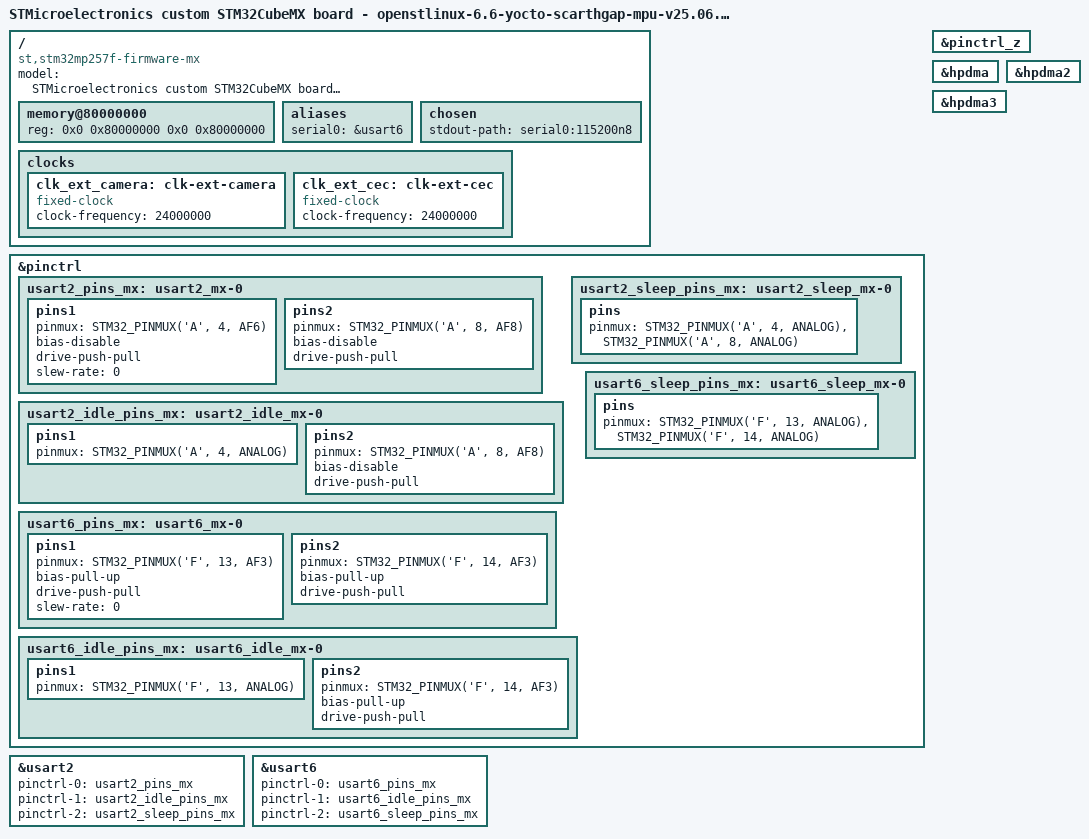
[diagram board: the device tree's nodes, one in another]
// SPDX-License-Identifier: (GPL-2.0-only OR BSD-3-Clause)
/*
 * Copyright (C) 2026, STMicroelectronics - All Rights Reserved
 * Author: STM32CubeMX code generation for STMicroelectronics.
 */

/* For more information on Device Tree configuration, please refer to
 * https://wiki.st.com/stm32mpu/wiki/Category:Device_tree_configuration
 */

/dts-v1/;

#include <dt-bindings/pinctrl/stm32-pinfunc.h>
#include "stm32mp257.dtsi"
#include "stm32mp25xf.dtsi"
#include "stm32mp257f-firmware-mx-resmem.dtsi"
#include "stm32mp25xxak-pinctrl.dtsi"

/* USER CODE BEGIN includes */
/* USER CODE END includes */

/ {
	model = "STMicroelectronics custom STM32CubeMX board - openstlinux-6.6-yocto-scarthgap-mpu-v25.06.11";
	compatible = "st,stm32mp257f-firmware-mx", "st,stm32mp257";

	memory@80000000 {
		device_type = "memory";
		reg = <0x0 0x80000000 0x0 0x80000000>;

		/* USER CODE BEGIN memory */
		/* USER CODE END memory */
	};

	/* USER CODE BEGIN root */
	aliases{
		serial0 = &usart6;
	};

	chosen{
		stdout-path = "serial0:115200n8";
	};
	/* USER CODE END root */

	clocks{

		/* USER CODE BEGIN clocks */
		clk_ext_camera:clk-ext-camera{
			#clock-cells = <0>;
			compatible = "fixed-clock";
			clock-frequency = <24000000>;
		};

		clk_ext_cec:clk-ext-cec{
			#clock-cells = <0>;
			compatible = "fixed-clock";
			clock-frequency = <24000000>;
		};
		/* USER CODE END clocks */
	};

}; /*root*/

&pinctrl {

	usart2_pins_mx: usart2_mx-0 {
		pins1 {
			pinmux = <STM32_PINMUX('A', 4, AF6)>; /* USART2_TX */
			bias-disable;
			drive-push-pull;
			slew-rate = <0>;
		};
		pins2 {
			pinmux = <STM32_PINMUX('A', 8, AF8)>; /* USART2_RX */
			bias-disable;
			drive-push-pull;
		};
	};

	usart2_idle_pins_mx: usart2_idle_mx-0 {
		pins1 {
			pinmux = <STM32_PINMUX('A', 4, ANALOG)>; /* USART2_TX */
		};
		pins2 {
			pinmux = <STM32_PINMUX('A', 8, AF8)>; /* USART2_RX */
			bias-disable;
			drive-push-pull;
		};
	};

	usart2_sleep_pins_mx: usart2_sleep_mx-0 {
		pins {
			pinmux = <STM32_PINMUX('A', 4, ANALOG)>, /* USART2_TX */
					 <STM32_PINMUX('A', 8, ANALOG)>; /* USART2_RX */
		};
	};

	usart6_pins_mx: usart6_mx-0 {
		pins1 {
			pinmux = <STM32_PINMUX('F', 13, AF3)>; /* USART6_TX */
			bias-pull-up;
			drive-push-pull;
			slew-rate = <0>;
		};
		pins2 {
			pinmux = <STM32_PINMUX('F', 14, AF3)>; /* USART6_RX */
			bias-pull-up;
			drive-push-pull;
		};
	};

	usart6_idle_pins_mx: usart6_idle_mx-0 {
		pins1 {
			pinmux = <STM32_PINMUX('F', 13, ANALOG)>; /* USART6_TX */
		};
		pins2 {
			pinmux = <STM32_PINMUX('F', 14, AF3)>; /* USART6_RX */
			bias-pull-up;
			drive-push-pull;
		};
	};

	usart6_sleep_pins_mx: usart6_sleep_mx-0 {
		pins {
			pinmux = <STM32_PINMUX('F', 13, ANALOG)>, /* USART6_TX */
					 <STM32_PINMUX('F', 14, ANALOG)>; /* USART6_RX */
		};
	};

	/* USER CODE BEGIN pinctrl */
	/* USER CODE END pinctrl */
};

&pinctrl_z {
	/* USER CODE BEGIN pinctrl_z */
	/* USER CODE END pinctrl_z */
};

&hpdma {
	status = "okay";

	/* USER CODE BEGIN hpdma */
	/* USER CODE END hpdma */
};

&hpdma2 {
	status = "okay";

	/* USER CODE BEGIN hpdma2 */
	/* USER CODE END hpdma2 */
};

&hpdma3 {
	status = "okay";

	/* USER CODE BEGIN hpdma3 */
	/* USER CODE END hpdma3 */
};

&usart2 {
	pinctrl-names = "default", "idle", "sleep";
	pinctrl-0 = <&usart2_pins_mx>;
	pinctrl-1 = <&usart2_idle_pins_mx>;
	pinctrl-2 = <&usart2_sleep_pins_mx>;
	status = "okay";

	/* USER CODE BEGIN usart2 */
	/* USER CODE END usart2 */
};

&usart6 {
	pinctrl-names = "default", "idle", "sleep";
	pinctrl-0 = <&usart6_pins_mx>;
	pinctrl-1 = <&usart6_idle_pins_mx>;
	pinctrl-2 = <&usart6_sleep_pins_mx>;
	status = "okay";

	/* USER CODE BEGIN usart6 */
	/* USER CODE END usart6 */
};

/* USER CODE BEGIN addons */
/* USER CODE END addons */

